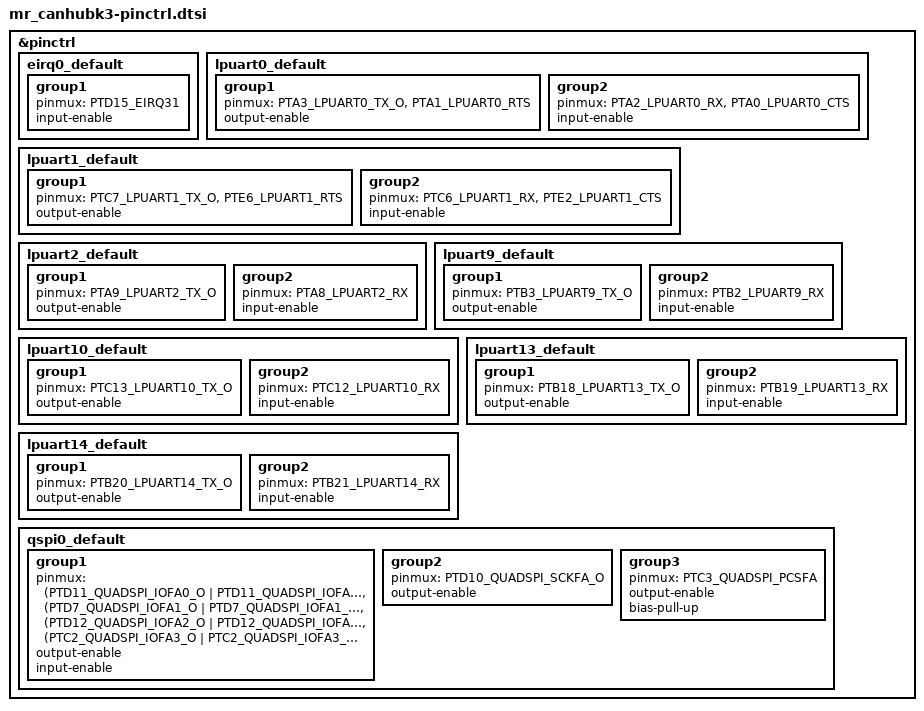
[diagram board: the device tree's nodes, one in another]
/*
 * Copyright 2023 NXP
 *
 * SPDX-License-Identifier: Apache-2.0
 */

#include <nxp/s32/S32K344-172MQFP-pinctrl.h>

&pinctrl {
	eirq0_default: eirq0_default {
		group1 {
			pinmux = <PTD15_EIRQ31>;
			input-enable;
		};
	};

	lpuart0_default: lpuart0_default {
		group1 {
			pinmux = <PTA3_LPUART0_TX_O>, <PTA1_LPUART0_RTS>;
			output-enable;
		};
		group2 {
			pinmux = <PTA2_LPUART0_RX>, <PTA0_LPUART0_CTS>;
			input-enable;
		};
	};

	lpuart1_default: lpuart1_default {
		group1 {
			pinmux = <PTC7_LPUART1_TX_O>, <PTE6_LPUART1_RTS>;
			output-enable;
		};
		group2 {
			pinmux = <PTC6_LPUART1_RX>, <PTE2_LPUART1_CTS>;
			input-enable;
		};
	};

	lpuart2_default: lpuart2_default {
		group1 {
			pinmux = <PTA9_LPUART2_TX_O>;
			output-enable;
		};
		group2 {
			pinmux = <PTA8_LPUART2_RX>;
			input-enable;
		};
	};

	lpuart9_default: lpuart9_default {
		group1 {
			pinmux = <PTB3_LPUART9_TX_O>;
			output-enable;
		};
		group2 {
			pinmux = <PTB2_LPUART9_RX>;
			input-enable;
		};
	};

	lpuart10_default: lpuart10_default {
		group1 {
			pinmux = <PTC13_LPUART10_TX_O>;
			output-enable;
		};
		group2 {
			pinmux = <PTC12_LPUART10_RX>;
			input-enable;
		};
	};

	lpuart13_default: lpuart13_default {
		group1 {
			pinmux = <PTB18_LPUART13_TX_O>;
			output-enable;
		};
		group2 {
			pinmux = <PTB19_LPUART13_RX>;
			input-enable;
		};
	};

	lpuart14_default: lpuart14_default {
		group1 {
			pinmux = <PTB20_LPUART14_TX_O>;
			output-enable;
		};
		group2 {
			pinmux = <PTB21_LPUART14_RX>;
			input-enable;
		};
	};

	qspi0_default: qspi0_default {
		group1 {
			pinmux = <(PTD11_QUADSPI_IOFA0_O | PTD11_QUADSPI_IOFA0_I)>,
				<(PTD7_QUADSPI_IOFA1_O | PTD7_QUADSPI_IOFA1_I)>,
				<(PTD12_QUADSPI_IOFA2_O | PTD12_QUADSPI_IOFA2_I)>,
				<(PTC2_QUADSPI_IOFA3_O | PTC2_QUADSPI_IOFA3_I)>;
			output-enable;
			input-enable;
		};
		group2 {
			pinmux = <PTD10_QUADSPI_SCKFA_O>;
			output-enable;
		};
		group3 {
			pinmux = <PTC3_QUADSPI_PCSFA>;
			output-enable;
			bias-pull-up;
		};
	};
};
